# ATxmega192C3 device description
Architecture: AVR8_XMEGA; Family: AVR XMEGA
Registers are 8-bit, access not given, no defined reset value unless marked. A register's access mark holds for its fields unless they carry their own. Offsets are from the block's base; [hi:lo] are bit positions; {n}, {i} and the like mark numbered series; 'fields as' and 'values as' point back to an identical list.

## MCU — MCU Control
Instances: MCU 0x0090
{0x0+i} DEVID{i} (i=0..2) — Device ID byte {i}
0x03 REVID — Revision ID
0x07 ANAINIT — Analog Startup Delay
  [1:0] STARTUPDLYA — Analog startup delay Port A
0x08 EVSYSLOCK — Event System Lock
  [0] EVSYS0LOCK — Event Channel 0-3 Lock
0x09 AWEXLOCK
  [0] AWEXCLOCK — AWeX on T/C C0 Lock

## PMIC — Programmable Multi-level Interrupt Controller
Instances: PMIC 0x00A0
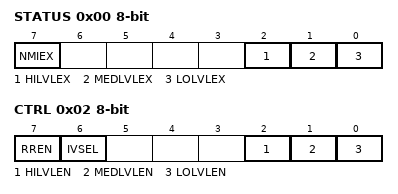
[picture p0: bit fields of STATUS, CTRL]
0x00 STATUS
  [7] NMIEX — Non-maskable Interrupt Executing
  [2] HILVLEX — High Level Interrupt Executing
  [1] MEDLVLEX — Medium Level Interrupt Executing
  [0] LOLVLEX — Low Level Interrupt Executing
0x01 INTPRI — Interrupt Priority
0x02 CTRL — Control Register
  [7] RREN — Round-Robin Priority Enable
  [6] IVSEL — Interrupt Vector Select
  [2] HILVLEN — High Level Enable
  [1] MEDLVLEN — Medium Level Enable
  [0] LOLVLEN — Low Level Enable

## PORTCFG — I/O port Configuration
Instances: PORTCFG 0x00B0
0x00 MPCMASK — Multi-pin Configuration Mask
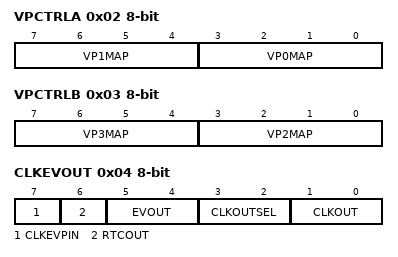
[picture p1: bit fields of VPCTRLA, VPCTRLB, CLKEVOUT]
0x02 VPCTRLA — Virtual Port Control Register A
  [7:4] VP1MAP — Virtual Port 1 Mapping
    0=PORTA (Mapped To PORTA); 1=PORTB (Mapped To PORTB); 2=PORTC (Mapped To PORTC); 3=PORTD (Mapped To PORTD); 4=PORTE (Mapped To PORTE); 5=PORTF (Mapped To PORTF); 6=PORTG (Mapped To PORTG); 7=PORTH (Mapped To PORTH); 8=PORTJ (Mapped To PORTJ); 9=PORTK (Mapped To PORTK); 10=PORTL (Mapped To PORTL); 11=PORTM (Mapped To PORTM); 12=PORTN (Mapped To PORTN); 13=PORTP (Mapped To PORTP); 14=PORTQ (Mapped To PORTQ); 15=PORTR (Mapped To PORTR)
  [3:0] VP0MAP — Virtual Port 0 Mapping
    values as VP1MAP
0x03 VPCTRLB — Virtual Port Control Register B
  [7:4] VP3MAP — Virtual Port 3 Mapping
    values as VPCTRLA.VP1MAP
  [3:0] VP2MAP — Virtual Port 2 Mapping
    values as VPCTRLA.VP1MAP
0x04 CLKEVOUT — Clock and Event Out Register
  [7] CLKEVPIN — Peripheral Clock and Event Output pin Select
  [6] RTCOUT — RTC Clock Output
  [5:4] EVOUT — Event Output Port
    0=OFF (Event Output Disabled); 1=PC7 (Event Channel 7 Output on Port C pin 7); 2=PD7 (Event Channel 7 Output on Port D pin 7); 3=PE7 (Event Channel 7 Output on Port E pin 7)
  [3:2] CLKOUTSEL — Peripheral Clock Output Select
    0=CLK1X (1x Peripheral Clock Output to pin); 1=CLK2X (2x Peripheral Clock Output to pin); 2=CLK4X (4x Peripheral Clock Output to pin)
  [1:0] CLKOUT — Peripheral Clock Output Port
    0=OFF (System Clock Output Disabled); 1=PC7 (System Clock Output on Port C pin 7); 2=PD7 (System Clock Output on Port D pin 7); 3=PE7 (System Clock Output on Port E pin 7)
0x06 EVOUTSEL — Event Output Select
  [2:0] EVOUTSEL
    {v}=Event Channel {v} output to pin (v=0..3)

## CRC — Cyclic Redundancy Checker
Instances: CRC 0x0D0
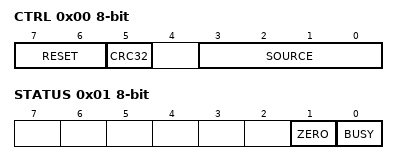
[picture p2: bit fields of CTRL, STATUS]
0x00 CTRL — Control Register
  [7:6] RESET
    0=NO (No Reset); 2=Reset CRC with CHECKSUM to all zeros; 3=Reset CRC with CHECKSUM to all ones
  [5] CRC32 — CRC Mode
  [3:0] SOURCE — Input Source
    0=DISABLE (Disabled); 1=IO (I/O Interface); 2=FLASH
0x01 STATUS
  [1] ZERO — Zero detection
  [0] BUSY
0x03 DATAIN — Data Input
{0x4+i} CHECKSUM{i} (i=0..3) — Checksum byte {i}

## EVSYS — Event System
Instances: EVSYS 0x0180
{0x0+i} CH{i}MUX (i=0..3) — Event Channel {i} Multiplexer
  [7:0] CHMUX
    0=OFF; 8=RTC_OVF (RTC Overflow); 9=RTC_CMP (RTC Compare Match); 10=USB (USB Setup, SOF, CRC error and UNF/OVF); 16=ACA_CH0 (Analog Comparator A Channel 0); 17=ACA_CH1 (Analog Comparator A Channel 1); 18=ACA_WIN (Analog Comparator A Window); 32=ADCA_CH0 (ADC A Channel); {v}=PORTA_PIN{v-80} (v=80..87); {v}=PORTB_PIN{v-88} (v=88..95); {v}=PORTC_PIN{v-96} (v=96..103); {v}=PORTD_PIN{v-104} (v=104..111); {v}=PORTE_PIN{v-112} (v=112..119); {v}=PORTF_PIN{v-120} (v=120..127); 128=PRESCALER_1 (Prescaler, divide by 1); 129=PRESCALER_2 (Prescaler, divide by 2); 130=PRESCALER_4 (Prescaler, divide by 4); 131=PRESCALER_8 (Prescaler, divide by 8); 132=PRESCALER_16 (Prescaler, divide by 16); 133=PRESCALER_32 (Prescaler, divide by 32); 134=PRESCALER_64 (Prescaler, divide by 64); 135=PRESCALER_128 (Prescaler, divide by 128); 136=PRESCALER_256 (Prescaler, divide by 256); 137=PRESCALER_512 (Prescaler, divide by 512); 138=PRESCALER_1024 (Prescaler, divide by 1024); 139=PRESCALER_2048 (Prescaler, divide by 2048); 140=PRESCALER_4096 (Prescaler, divide by 4096); 141=PRESCALER_8192 (Prescaler, divide by 8192); 142=PRESCALER_16384 (Prescaler, divide by 16384); 143=PRESCALER_32768 (Prescaler, divide by 32768); 192=TCC0_OVF (Timer/Counter C0 Overflow); 193=TCC0_ERR (Timer/Counter C0 Error); 196=TCC0_CCA (Timer/Counter C0 Compare or Capture A); 197=TCC0_CCB (Timer/Counter C0 Compare or Capture B); 198=TCC0_CCC (Timer/Counter C0 Compare or Capture C); 199=TCC0_CCD (Timer/Counter C0 Compare or Capture D); 200=TCC1_OVF (Timer/Counter C1 Overflow); 201=TCC1_ERR (Timer/Counter C1 Error); 204=TCC1_CCA (Timer/Counter C1 Compare or Capture A); 205=TCC1_CCB (Timer/Counter C1 Compare or Capture B); 208=TCD0_OVF (Timer/Counter D0 Overflow); 209=TCD0_ERR (Timer/Counter D0 Error); 212=TCD0_CCA (Timer/Counter D0 Compare or Capture A); 213=TCD0_CCB (Timer/Counter D0 Compare or Capture B); 214=TCD0_CCC (Timer/Counter D0 Compare or Capture C); 215=TCD0_CCD (Timer/Counter D0 Compare or Capture D); 224=TCE0_OVF (Timer/Counter E0 Overflow); 225=TCE0_ERR (Timer/Counter E0 Error); 228=TCE0_CCA (Timer/Counter E0 Compare or Capture A); 229=TCE0_CCB (Timer/Counter E0 Compare or Capture B); 230=TCE0_CCC (Timer/Counter E0 Compare or Capture C); 231=TCE0_CCD (Timer/Counter E0 Compare or Capture D); 240=TCF0_OVF (Timer/Counter F0 Overflow); 241=TCF0_ERR (Timer/Counter F0 Error); 244=TCF0_CCA (Timer/Counter F0 Compare or Capture A); 245=TCF0_CCB (Timer/Counter F0 Compare or Capture B); 246=TCF0_CCC (Timer/Counter F0 Compare or Capture C); 247=TCF0_CCD (Timer/Counter F0 Compare or Capture D)
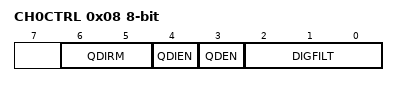
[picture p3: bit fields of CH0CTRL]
0x08 CH0CTRL — Channel 0 Control Register
  [6:5] QDIRM — Quadrature Decoder Index Recognition Mode
    0=QDPH0 = 0, QDPH90 = 0; 1=QDPH0 = 0, QDPH90 = 1; 2=QDPH0 = 1, QDPH90 = 0; 3=QDPH0 = 1, QDPH90 = 1
  [4] QDIEN — Quadrature Decoder Index Enable
  [3] QDEN — Quadrature Decoder Enable
  [2:0] DIGFILT — Digital Filter
    0=1SAMPLE; {v}={v+1}SAMPLES (v=1..7)
{0x8+i} CH{i}CTRL (i=1..3) — Channel {i} Control Register
  [2:0] DIGFILT — Digital Filter
    0=1SAMPLE; {v}={v+1}SAMPLES (v=1..7)
0x10 STROBE — Event Strobe
0x11 DATA — Event Data
